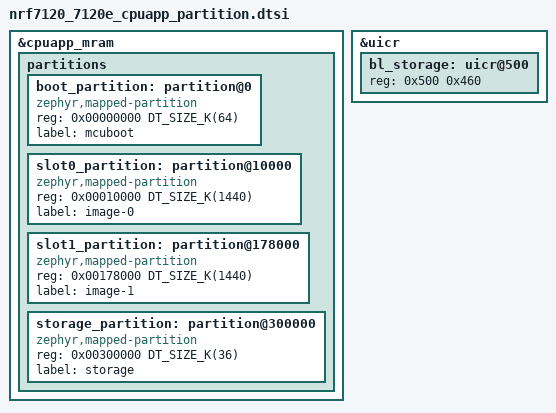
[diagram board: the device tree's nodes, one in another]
/*
 * Copyright (c) 2025 Nordic Semiconductor ASA
 *
 * SPDX-License-Identifier: Apache-2.0
 *
 * Default memory partitioning for nRF7120 application CPU.
 */

/* These partition sizes assume no FLPR area in MRAM */
&cpuapp_mram {
	partitions {
		ranges;
		#address-cells = <1>;
		#size-cells = <1>;

		boot_partition: partition@0 {
			compatible = "zephyr,mapped-partition";
			reg = <0x00000000 DT_SIZE_K(64)>;
			label = "mcuboot";
		};

		slot0_partition: partition@10000 {
			compatible = "zephyr,mapped-partition";
			reg = <0x00010000 DT_SIZE_K(1440)>;
			label = "image-0";
		};

		slot1_partition: partition@178000 {
			compatible = "zephyr,mapped-partition";
			reg = <0x00178000 DT_SIZE_K(1440)>;
			label = "image-1";
		};

		storage_partition: partition@300000 {
			compatible = "zephyr,mapped-partition";
			reg = <0x00300000 DT_SIZE_K(36)>;
			label = "storage";
		};
	};
};

&uicr {
	bl_storage: uicr@500 {
		reg = <0x500 0x460>;
	};
};
